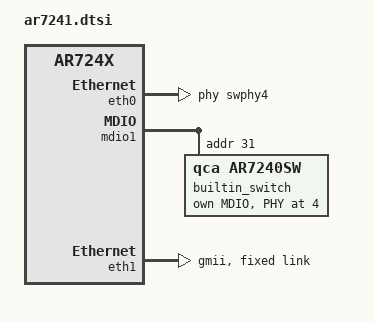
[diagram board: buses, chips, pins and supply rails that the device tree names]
// SPDX-License-Identifier: GPL-2.0-or-later OR MIT

#include "ar724x.dtsi"

/ {
	usb_phy: usb-phy {
		compatible = "qca,ar7200-usb-phy";

		reset-names = "usb-phy", "usb-suspend-override";
		resets = <&rst 4>, <&rst 3>;

		#phy-cells = <0>;

		status = "disabled";
	};
};

&gpio {
	ngpios = <20>;
};

&ahb {
	usb: usb@1b000000 {
		compatible = "generic-ehci";
		reg = <0x1b000000 0x1000>;

		interrupts = <3>;

		resets = <&rst 5>;
		reset-names = "usb-host";

		has-transaction-translator;
		caps-offset = <0x100>;

		phy-names = "usb-phy";
		phys = <&usb_phy>;

		status = "disabled";
	};
};

&eth0 {
	compatible = "qca,ar7241-eth", "syscon";

	pll-data = <0x00110000 0x00001099 0x00991099>;

	resets = <&rst 9>;
	reset-names = "mac";
	phy-handle = <&swphy4>;
};

&mdio1 {
	status = "okay";

	resets = <&rst 23>;
	reset-names = "mdio";
	builtin-switch;

	builtin_switch: switch0@1f {
		compatible = "qca,ar7240sw";

		reg = <0x1f>;
		resets = <&rst 8>;
		reset-names = "switch";
		qca,mib-poll-interval = <500>;

		mdio-bus {
			#address-cells = <1>;
			#size-cells = <0>;

			swphy4: ethernet-phy@4 {
				reg = <4>;
				phy-mode = "mii";
			};
		};
	};
};

&eth1 {
	status = "okay";

	compatible = "qca,ar7241-eth", "syscon";

	pll-data = <0x00110000 0x00001099 0x00991099>;

	resets = <&rst 13>;
	reset-names = "mac";

	phy-mode = "gmii";

	fixed-link {
		speed = <1000>;
		full-duplex;
	};
};
